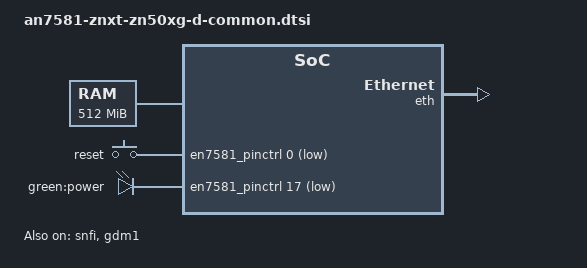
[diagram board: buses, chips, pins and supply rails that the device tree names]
// SPDX-License-Identifier: (GPL-2.0-only OR BSD-2-Clause)

#include <dt-bindings/gpio/gpio.h>
#include <dt-bindings/input/input.h>
#include "en7581.dtsi"

/ {
	aliases {
		serial0 = &uart1;
	};

	chosen {
		stdout-path = "serial0:115200n8";
	};

	/* 512 MiB is the fallback until BL2 publishes the detected capacity. */
	memory@80000000 {
		device_type = "memory";
		reg = <0x0 0x80000000 0x0 0x20000000>;
	};

	keys {
		compatible = "gpio-keys";

		key-reset {
			label = "reset";
			linux,code = <KEY_RESTART>;
			gpios = <&en7581_pinctrl 0 GPIO_ACTIVE_LOW>;
		};
	};

	leds {
		compatible = "gpio-leds";

		led-power {
			label = "green:power";
			gpios = <&en7581_pinctrl 17 GPIO_ACTIVE_LOW>;
			default-state = "keep";
		};
	};
};

&en7581_pinctrl {
	gpio-ranges = <&en7581_pinctrl 0 13 50>;
};

&snfi {
	status = "okay";
};

&spi_nand {
	/* ID 2c:24 covers multiple geometries; the board compatible selects F50L2G41XA. */
	compatible = "esmt,f50l2g41xa", "spi-nand";

	partitions {
		compatible = "fixed-partitions";
		#address-cells = <1>;
		#size-cells = <1>;

		bl2@0 {
			label = "bl2";
			reg = <0x00000000 0x00020000>;
		};

		/* UBI owns every eraseblock after the BL2 preloader. */
		ubi@20000 {
			label = "ubi";
			reg = <0x00020000 0x00000000>;
		};
	};
};

&eth {
	status = "okay";
};

&gdm1 {
	status = "okay";
};
